# iom480ae register map
Registers are 32-bit, access not given, no defined reset value unless marked. A register's access mark holds for its fields unless they carry their own. Addresses are absolute; registers are grouped by the start of their names; [hi:lo] are bit positions.

## SPI2
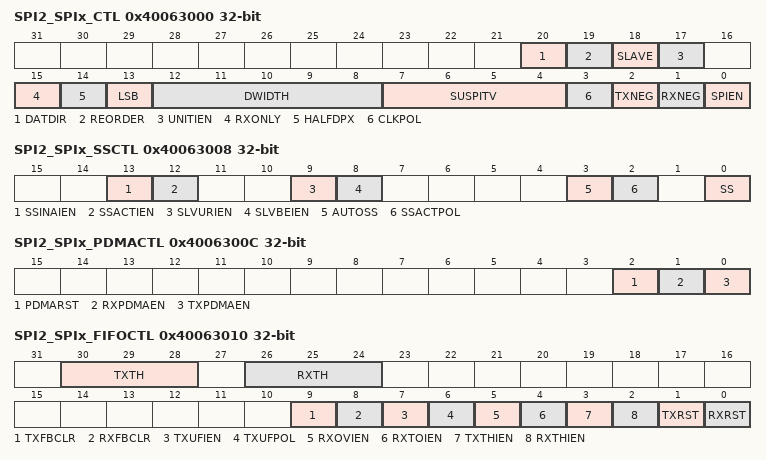
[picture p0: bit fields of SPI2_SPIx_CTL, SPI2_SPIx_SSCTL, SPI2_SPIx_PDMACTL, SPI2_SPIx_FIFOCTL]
0x40063000 SPI2_SPIx_CTL
  [20] DATDIR, [19] REORDER, [18] SLAVE, [17] UNITIEN, [15] RXONLY, [14] HALFDPX, [13] LSB, [12:8] DWIDTH, [7:4] SUSPITV, [3] CLKPOL, [2] TXNEG, [1] RXNEG, [0] SPIEN
0x40063004 SPI2_SPIx_CLKDIV
  [8:0] DIVIDER
0x40063008 SPI2_SPIx_SSCTL
  [13] SSINAIEN, [12] SSACTIEN, [9] SLVURIEN, [8] SLVBEIEN, [3] AUTOSS, [2] SSACTPOL, [0] SS
0x4006300C SPI2_SPIx_PDMACTL
  [2] PDMARST, [1] RXPDMAEN, [0] TXPDMAEN
0x40063010 SPI2_SPIx_FIFOCTL
  [30:28] TXTH, [26:24] RXTH, [9] TXFBCLR, [8] RXFBCLR, [7] TXUFIEN, [6] TXUFPOL, [5] RXOVIEN, [4] RXTOIEN, [3] TXTHIEN, [2] RXTHIEN, [1] TXRST, [0] RXRST
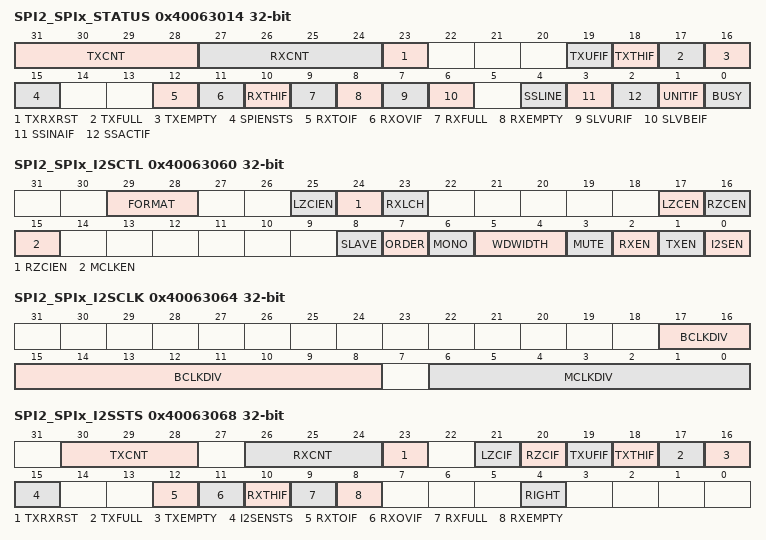
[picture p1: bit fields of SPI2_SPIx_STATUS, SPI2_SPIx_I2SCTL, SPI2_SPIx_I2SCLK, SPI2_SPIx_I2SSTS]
0x40063014 SPI2_SPIx_STATUS
  [31:28] TXCNT, [27:24] RXCNT, [23] TXRXRST, [19] TXUFIF, [18] TXTHIF, [17] TXFULL, [16] TXEMPTY, [15] SPIENSTS, [12] RXTOIF, [11] RXOVIF, [10] RXTHIF, [9] RXFULL, [8] RXEMPTY, [7] SLVURIF, [6] SLVBEIF, [4] SSLINE, [3] SSINAIF, [2] SSACTIF, [1] UNITIF, [0] BUSY
0x40063020 SPI2_SPIx_TX
0x40063030 SPI2_SPIx_RX
0x40063060 SPI2_SPIx_I2SCTL
  [29:28] FORMAT, [25] LZCIEN, [24] RZCIEN, [23] RXLCH, [17] LZCEN, [16] RZCEN, [15] MCLKEN, [8] SLAVE, [7] ORDER, [6] MONO, [5:4] WDWIDTH, [3] MUTE, [2] RXEN, [1] TXEN, [0] I2SEN
0x40063064 SPI2_SPIx_I2SCLK
  [17:8] BCLKDIV, [6:0] MCLKDIV
0x40063068 SPI2_SPIx_I2SSTS
  [30:28] TXCNT, [26:24] RXCNT, [23] TXRXRST, [21] LZCIF, [20] RZCIF, [19] TXUFIF, [18] TXTHIF, [17] TXFULL, [16] TXEMPTY, [15] I2SENSTS, [12] RXTOIF, [11] RXOVIF, [10] RXTHIF, [9] RXFULL, [8] RXEMPTY, [4] RIGHT

## SPI3
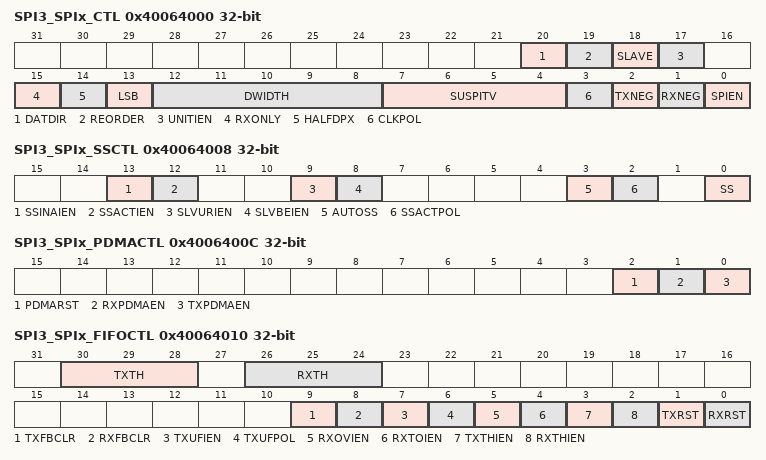
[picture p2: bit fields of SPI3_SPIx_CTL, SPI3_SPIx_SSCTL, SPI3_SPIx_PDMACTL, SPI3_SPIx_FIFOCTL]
0x40064000 SPI3_SPIx_CTL
  [20] DATDIR, [19] REORDER, [18] SLAVE, [17] UNITIEN, [15] RXONLY, [14] HALFDPX, [13] LSB, [12:8] DWIDTH, [7:4] SUSPITV, [3] CLKPOL, [2] TXNEG, [1] RXNEG, [0] SPIEN
0x40064004 SPI3_SPIx_CLKDIV
  [8:0] DIVIDER
0x40064008 SPI3_SPIx_SSCTL
  [13] SSINAIEN, [12] SSACTIEN, [9] SLVURIEN, [8] SLVBEIEN, [3] AUTOSS, [2] SSACTPOL, [0] SS
0x4006400C SPI3_SPIx_PDMACTL
  [2] PDMARST, [1] RXPDMAEN, [0] TXPDMAEN
0x40064010 SPI3_SPIx_FIFOCTL
  [30:28] TXTH, [26:24] RXTH, [9] TXFBCLR, [8] RXFBCLR, [7] TXUFIEN, [6] TXUFPOL, [5] RXOVIEN, [4] RXTOIEN, [3] TXTHIEN, [2] RXTHIEN, [1] TXRST, [0] RXRST
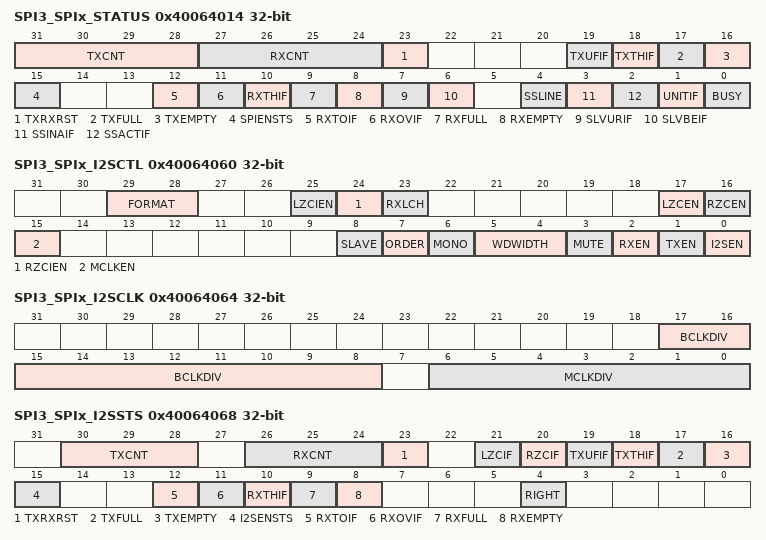
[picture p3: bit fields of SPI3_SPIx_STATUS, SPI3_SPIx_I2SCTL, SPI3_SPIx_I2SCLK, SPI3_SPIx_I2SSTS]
0x40064014 SPI3_SPIx_STATUS
  [31:28] TXCNT, [27:24] RXCNT, [23] TXRXRST, [19] TXUFIF, [18] TXTHIF, [17] TXFULL, [16] TXEMPTY, [15] SPIENSTS, [12] RXTOIF, [11] RXOVIF, [10] RXTHIF, [9] RXFULL, [8] RXEMPTY, [7] SLVURIF, [6] SLVBEIF, [4] SSLINE, [3] SSINAIF, [2] SSACTIF, [1] UNITIF, [0] BUSY
0x40064020 SPI3_SPIx_TX
0x40064030 SPI3_SPIx_RX
0x40064060 SPI3_SPIx_I2SCTL
  [29:28] FORMAT, [25] LZCIEN, [24] RZCIEN, [23] RXLCH, [17] LZCEN, [16] RZCEN, [15] MCLKEN, [8] SLAVE, [7] ORDER, [6] MONO, [5:4] WDWIDTH, [3] MUTE, [2] RXEN, [1] TXEN, [0] I2SEN
0x40064064 SPI3_SPIx_I2SCLK
  [17:8] BCLKDIV, [6:0] MCLKDIV
0x40064068 SPI3_SPIx_I2SSTS
  [30:28] TXCNT, [26:24] RXCNT, [23] TXRXRST, [21] LZCIF, [20] RZCIF, [19] TXUFIF, [18] TXTHIF, [17] TXFULL, [16] TXEMPTY, [15] I2SENSTS, [12] RXTOIF, [11] RXOVIF, [10] RXTHIF, [9] RXFULL, [8] RXEMPTY, [4] RIGHT

## QSPI0
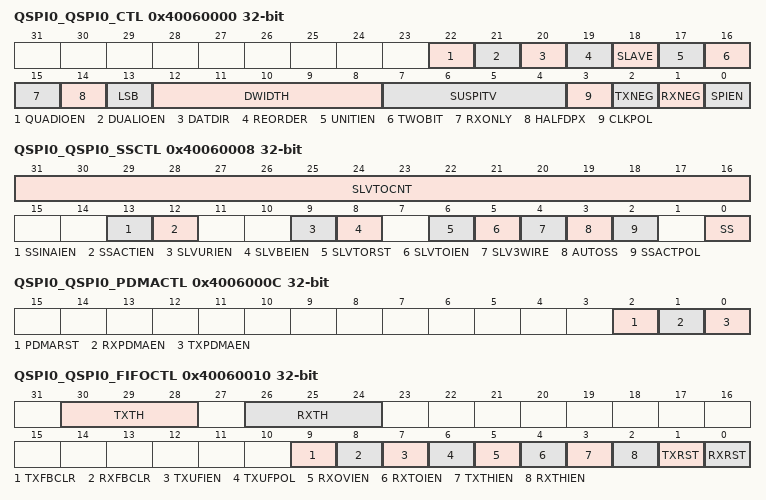
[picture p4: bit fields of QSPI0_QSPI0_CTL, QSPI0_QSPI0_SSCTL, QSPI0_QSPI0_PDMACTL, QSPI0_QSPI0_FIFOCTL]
0x40060000 QSPI0_QSPI0_CTL
  [22] QUADIOEN, [21] DUALIOEN, [20] DATDIR, [19] REORDER, [18] SLAVE, [17] UNITIEN, [16] TWOBIT, [15] RXONLY, [14] HALFDPX, [13] LSB, [12:8] DWIDTH, [7:4] SUSPITV, [3] CLKPOL, [2] TXNEG, [1] RXNEG, [0] SPIEN
0x40060004 QSPI0_QSPI0_CLKDIV
  [8:0] DIVIDER
0x40060008 QSPI0_QSPI0_SSCTL
  [31:16] SLVTOCNT, [13] SSINAIEN, [12] SSACTIEN, [9] SLVURIEN, [8] SLVBEIEN, [6] SLVTORST, [5] SLVTOIEN, [4] SLV3WIRE, [3] AUTOSS, [2] SSACTPOL, [0] SS
0x4006000C QSPI0_QSPI0_PDMACTL
  [2] PDMARST, [1] RXPDMAEN, [0] TXPDMAEN
0x40060010 QSPI0_QSPI0_FIFOCTL
  [30:28] TXTH, [26:24] RXTH, [9] TXFBCLR, [8] RXFBCLR, [7] TXUFIEN, [6] TXUFPOL, [5] RXOVIEN, [4] RXTOIEN, [3] TXTHIEN, [2] RXTHIEN, [1] TXRST, [0] RXRST
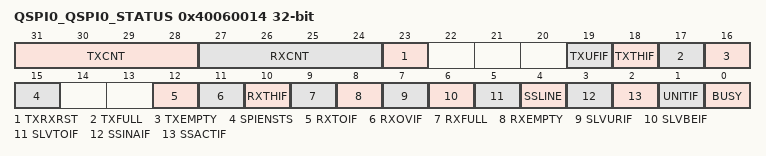
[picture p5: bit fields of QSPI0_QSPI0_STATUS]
0x40060014 QSPI0_QSPI0_STATUS
  [31:28] TXCNT, [27:24] RXCNT, [23] TXRXRST, [19] TXUFIF, [18] TXTHIF, [17] TXFULL, [16] TXEMPTY, [15] SPIENSTS, [12] RXTOIF, [11] RXOVIF, [10] RXTHIF, [9] RXFULL, [8] RXEMPTY, [7] SLVURIF, [6] SLVBEIF, [5] SLVTOIF, [4] SSLINE, [3] SSINAIF, [2] SSACTIF, [1] UNITIF, [0] BUSY
0x40060020 QSPI0_QSPI0_TX
0x40060030 QSPI0_QSPI0_RX
